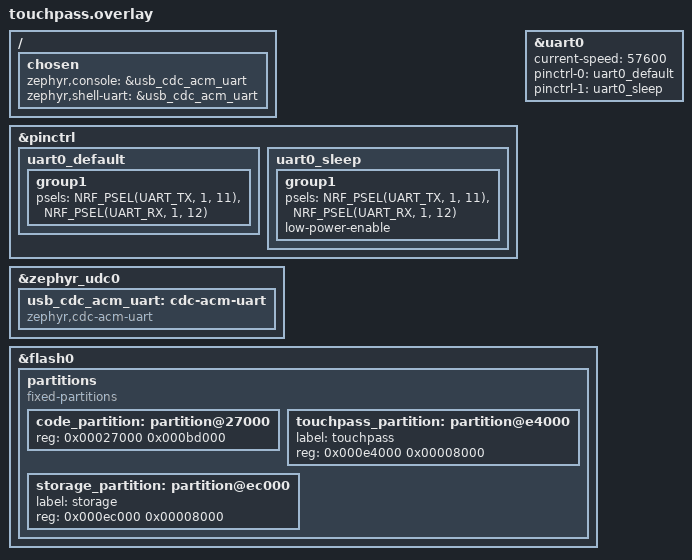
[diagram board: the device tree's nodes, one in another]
#include "touchpass.dtsi"

&pinctrl {
    uart0_default: uart0_default {
        group1 {
            psels = <NRF_PSEL(UART_TX, 1, 11)>,
                    <NRF_PSEL(UART_RX, 1, 12)>;
        };
    };

    uart0_sleep: uart0_sleep {
        group1 {
            psels = <NRF_PSEL(UART_TX, 1, 11)>,
                    <NRF_PSEL(UART_RX, 1, 12)>;
            low-power-enable;
        };
    };
};

// DCDC is enabled via Kconfig (CONFIG_BOARD_ENABLE_DCDC=y) in ZMK v0.3/Zephyr 3.5
// The reg0/reg1 nodes are not defined in this version's device tree.

&zephyr_udc0 {
    status = "okay";
    usb_cdc_acm_uart: cdc-acm-uart {
        compatible = "zephyr,cdc-acm-uart";
    };
};

/ {
    chosen {
        /* Disable default UART console to prevent boot hang if pins are used elsewhere */
        /* Console will be handled by USB CDC ACM (zephyr_udc0) */
        /delete-property/ zephyr,console;
        /delete-property/ zephyr,shell-uart;
        zephyr,console = &usb_cdc_acm_uart;
        zephyr,shell-uart = &usb_cdc_acm_uart;
    };
};

&uart0 {
    status = "okay";
    current-speed = <57600>;
    pinctrl-0 = <&uart0_default>;
    pinctrl-1 = <&uart0_sleep>;
    pinctrl-names = "default", "sleep";
};

&flash0 {
    partitions {
        compatible = "fixed-partitions";
        #address-cells = <1>;
        #size-cells = <1>;

        /* Overwrite code_partition to make space for touchpass_partition at the end */
        /* 0xe4000 - 0x27000 = 0xbd000 */
        code_partition: partition@27000 {
            reg = <0x00027000 0x000bd000>;
        };

        /* TouchPass finger data (NVS) — separate from ZMK settings NVS */
        touchpass_partition: partition@e4000 {
            label = "touchpass";
            reg = <0x000e4000 0x00008000>;
        };

        /* ZMK settings / BLE bonding (NVS) */
        storage_partition: partition@ec000 {
            label = "storage";
            reg = <0x000ec000 0x00008000>;
        };
    };
};
